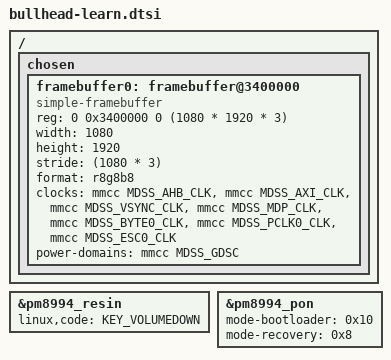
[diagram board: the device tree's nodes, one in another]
// SPDX-License-Identifier: GPL-2.0-only
#include <dt-bindings/clock/qcom,mmcc-msm8994.h>

/ {
	chosen {
		#address-cells = <2>;
		#size-cells = <2>;
		ranges;

		/* LK leaves the splash screen running here (cont_splash_mem). */
		framebuffer0: framebuffer@3400000 {
			compatible = "simple-framebuffer";
			reg = <0 0x3400000 0 (1080 * 1920 * 3)>;
			width = <1080>;
			height = <1920>;
			stride = <(1080 * 3)>;
			format = "r8g8b8";
			/* keep the display pipeline alive: there is no panel driver */
			clocks = <&mmcc MDSS_AHB_CLK>,
				 <&mmcc MDSS_AXI_CLK>,
				 <&mmcc MDSS_VSYNC_CLK>,
				 <&mmcc MDSS_MDP_CLK>,
				 <&mmcc MDSS_BYTE0_CLK>,
				 <&mmcc MDSS_PCLK0_CLK>,
				 <&mmcc MDSS_ESC0_CLK>;
			power-domains = <&mmcc MDSS_GDSC>;
		};
	};
};

/* Volume-down is wired to the PMIC "resin" line. */
&pm8994_resin {
	linux,code = <KEY_VOLUMEDOWN>;
	status = "okay";
};

/*
 * Reboot reasons for LK (aboot), as the LG 3.10 kernel stores them in the PMIC
 * (qpnp_pon_set_restart_reason): reason r becomes ((r & 7) << 4) | (r >> 3),
 * written to SOFT_RB_SPARE bits 7:1. bootloader (2) -> 0x40, recovery (1) ->
 * 0x20. qcom-pon writes magic << 2 to bits 7:2, hence 0x10 and 0x8.
 */
&pm8994_pon {
	mode-bootloader = <0x10>;
	mode-recovery = <0x8>;
};
